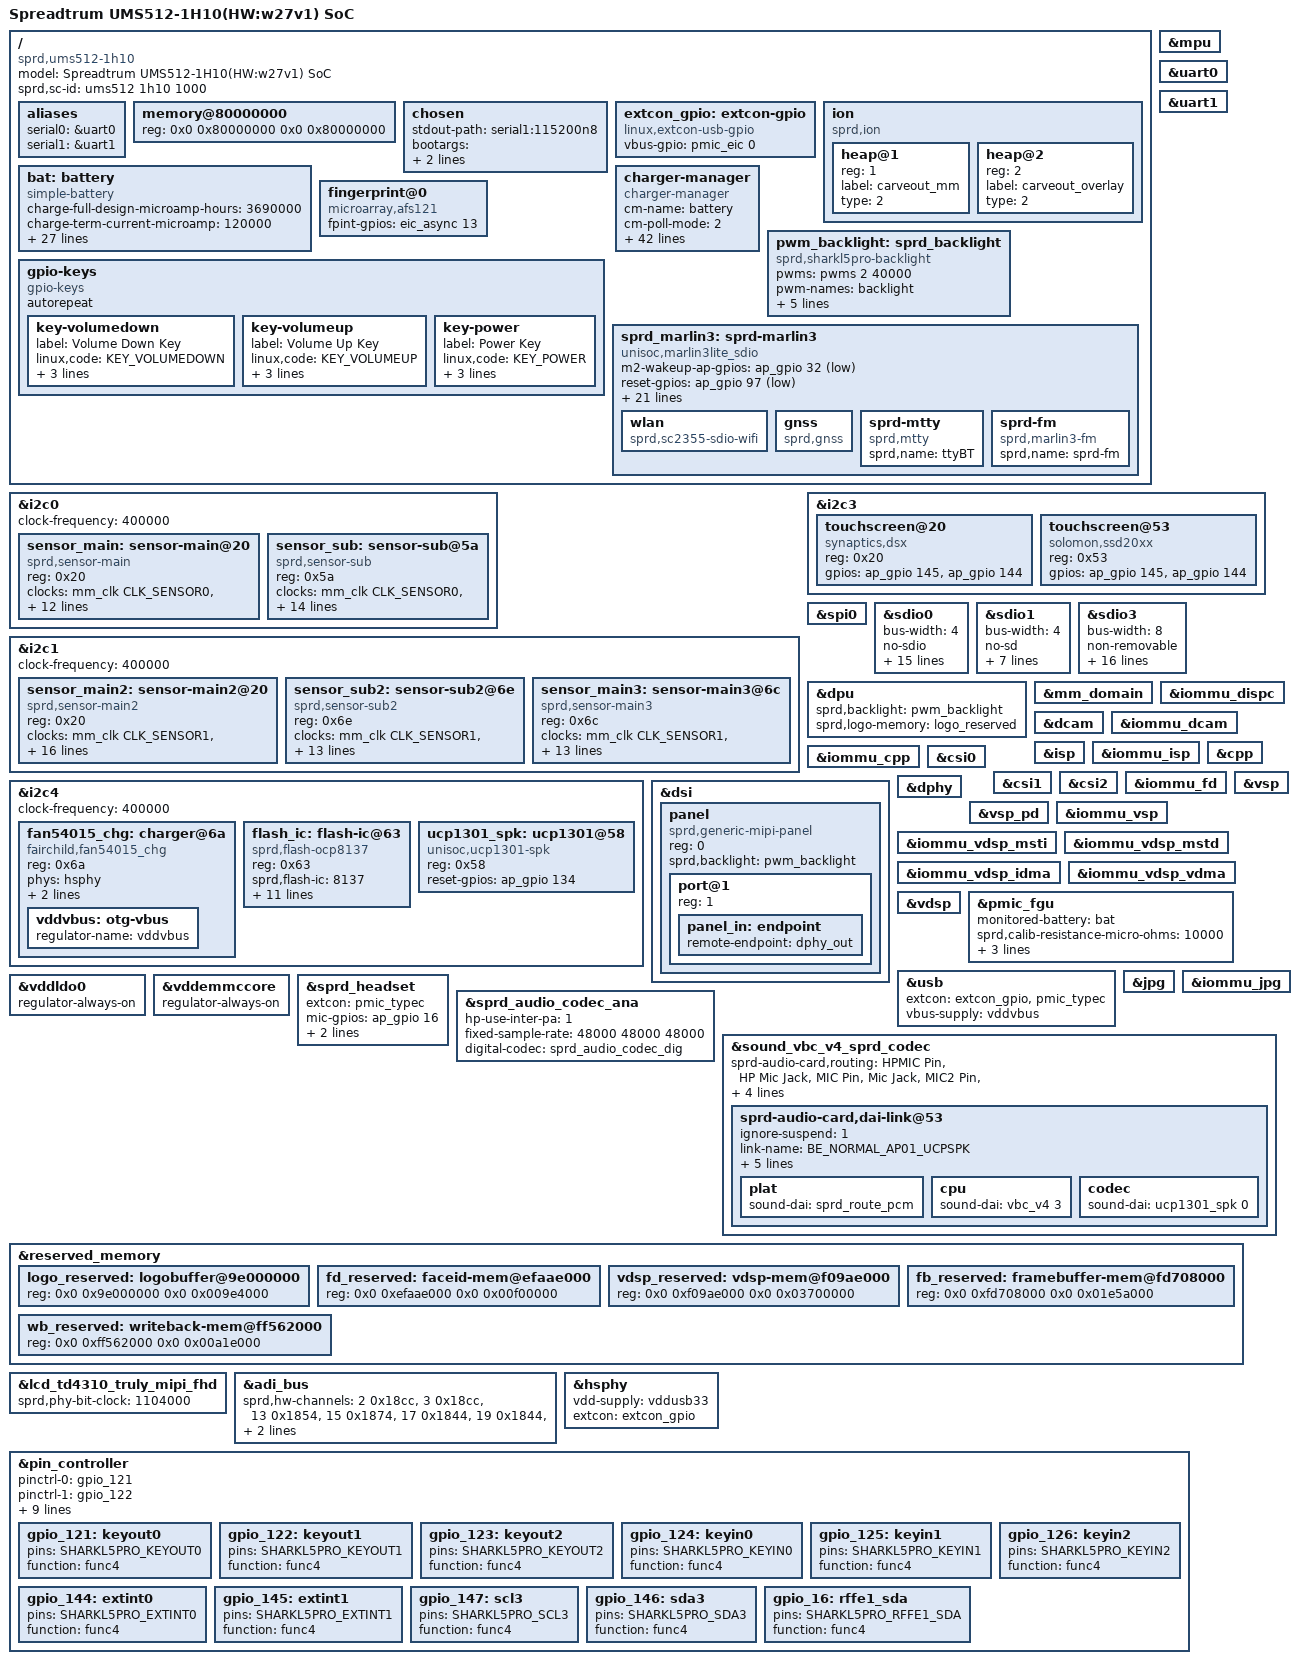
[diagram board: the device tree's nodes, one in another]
// SPDX-License-Identifier: GPL-2.0-only
/*
 * Unisoc UMS512-1h10 boards DTS file
 *
 * Copyright (C) 2020, Unisoc Inc.
 */

/dts-v1/;

#include <dt-bindings/clock/sprd,ums512-clk.h>
#include <dt-bindings/input/input.h>
#include <dt-bindings/gpio/gpio.h>
#include "ums512.dtsi"
#include "sc2730.dtsi"
#include "sprd-sound-fe-be.dtsi"
#include "ums512-mach.dtsi"
#include <dt-bindings/mfd/sprd,sc2730-regs.h>
#include <dt-bindings/mfd/sprd,sc2730-mask.h>

#include "lcd/lcd_td4310_truly_mipi_fhd.dtsi"
#include "lcd/lcd_ssd2092_truly_mipi_fhd.dtsi"

/ {
	model = "Spreadtrum UMS512-1H10(HW:w27v1) SoC";

	compatible = "sprd,ums512-1h10", "sprd,ums512";

	sprd,sc-id = "ums512 1h10 1000";

	aliases {
		serial0 = &uart0;
		serial1 = &uart1;
	};

	memory@80000000 {
		device_type = "memory";
		reg = <0x0 0x80000000 0x0 0x80000000>;
	};

	chosen: chosen {
		stdout-path = "serial1:115200n8";
		bootargs = "earlycon console=ttyS1,115200n8 loglevel=1 init=/init root=/dev/ram0 rw printk.devkmsg=on androidboot.boot_devices=soc/soc:ap-apb/71400000.sdio dummy_hcd.num=0";
	};

	extcon_gpio: extcon-gpio {
		compatible = "linux,extcon-usb-gpio";
		vbus-gpio = <&pmic_eic 0 GPIO_ACTIVE_HIGH>;
	};

	ion: ion {
		compatible = "sprd,ion";
		#address-cells = <1>;
		#size-cells = <0>;

		heap@1 {
			reg = <1>;
			label = "carveout_mm";
			type = <2>;
		};

		heap@2 {
			reg = <2>;
			label = "carveout_overlay";
			type = <2>;
		};
	};

	bat: battery {
		compatible = "simple-battery";
		charge-full-design-microamp-hours = <3690000>;
		charge-term-current-microamp = <120000>;
		constant-charge-voltage-max-microvolt = <4400000>;
		factory-internal-resistance-micro-ohms = <130000>;
		voltage-min-design-microvolt = <3450000>;
		ocv-capacity-celsius = <20>;
		ocv-capacity-table-0 = <4380000 100>, <4317000 95>, <4258000 90>,
					<4200000 85>, <4145000 80>, <4092000 75>,
					<4047000 70>, <3990000 65>, <3955000 60>,
					<3900000 55>, <3861000 50>, <3834000 45>,
					<3813000 40>, <3796000 35>, <3783000 30>,
					<3770000 25>, <3752000 20>, <3730000 15>,
					<3698000 10>, <3687000 5>, <3400000 0>;
		voltage-temp-table = <1095000 800>, <986000 850>, <878000 900>,
				      <775000 950>, <678000 1000>, <590000 1050>,
				      <510000 1100>, <440000 1150>, <378000 1200>,
				      <324000 1250>, <278000 1300>, <238000 1350>,
				      <204000 1400>, <175000 1450>, <150000 1500>,
				      <129000 1550>, <111000 1600>, <96000 1650>;
		capacity-temp-table = <45 100>, <25 100>, <10 98>, <0 93>, <(-10) 85>, <(-20) 64>;
		resistance-temp-table = <45 77>, <25 100>, <10 546>, <0 769>, <(-10) 892>, <(-20) 923>;
		charge-sdp-current-microamp = <500000 500000>;
		charge-dcp-current-microamp = <1150000 3000000>;
		charge-cdp-current-microamp = <1150000 1150000>;
		charge-unknown-current-microamp = <1050000 1050000>;
	};

	charger-manager {
		compatible = "charger-manager";
		cm-name = "battery";
		cm-poll-mode = <2>;
		cm-poll-interval = <15000>;
		cm-battery-stat = <2>;

		cm-fullbatt-vchkdrop-ms = <30000>;
		cm-fullbatt-vchkdrop-volt = <60000>;
		cm-fullbatt-voltage = <4350000>;
		cm-fullbatt-current = <120000>;
		cm-fullbatt-capacity = <100>;

		cm-num-chargers = <1>;
		cm-chargers = "fan54015_charger";
		cm-fuel-gauge = "sc27xx-fgu";

		/* in deci centigrade */
		cm-battery-cold = <200>;
		cm-battery-cold-in-minus;
		cm-battery-hot = <800>;
		cm-battery-temp-diff = <100>;

		/* Allow charging for 6hr */
		cm-charging-max = <21600000>;
		/* recovery charging after stop charging 45min */
		cm-discharging-max = <2700000>;

		/* the interval to feed charger watchdog */
		cm-wdt-interval = <60>;

		/* drop voltage in microVolts to allow shutdown */
		cm-shutdown-voltage = <3100000>;

		/* when 99% of the time is exceeded, it will be forced to 100% */
		cm-tickle-time-out = <1500>;

		/* how much time to allow capacity change */
		cm-one-cap-time = <30>;

		/* when the safe charging voltage is exceeded, stop charging */
		cm-charge-voltage-max = <6500000>;
		/* drop voltage in microVolts to restart charging */
		cm-charge-voltage-drop = <700000>;
		cm-dcp-jeita-temp-table = <1000 1030 0 4400000>, <1150 1180 700000 4400000>,
			<1450 1420 1150000 4400000>, <1600 1570 700000 4100000>;
		cm-sdp-jeita-temp-table = <1000 1030 0 4400000>, <1150 1180 500000 4400000>,
			<1450 1420 500000 4400000>, <1600 1570 500000 4100000>;
		cm-cdp-jeita-temp-table = <1000 1030 0 4400000>, <1150 1180 700000 4400000>,
			<1450 1420 1150000 4400000>, <1600 1570 700000 4100000>;
		cm-unknown-jeita-temp-table = <1000 1030 0 4400000>, <1150 1180 700000 4400000>,
			<1450 1420 1050000 4400000>, <1600 1570 700000 4100000>;

		monitored-battery = <&bat>;

		cm-cap-remap-table = <1 2 3>, <2 3 2>, <98 99 2>, <99 100 3>;

	};

	fingerprint@0 {
		compatible = "microarray,afs121";
		fpint-gpios = <&eic_async 13 0>;
	};

	pwm_backlight: sprd_backlight {
		compatible = "sprd,sharkl5pro-backlight";
		pwms = <&pwms 2 40000>;
		pwm-names = "backlight";
		sprd,max-brightness-level = <880>;
		default-brightness-level = <250>;
		sprd,brightness-scale = <1023>;
		brightness-levels = <
					  0   3   4   5   6   7
			  8   9  10  11  12  13  14  15  16  17
			 18  19  20  21  22  23  24  25  26  27
			 28  29  31  33  35  37  39  41  43  45
			 46  48  50  52  54  56  58  60  62  64
			 66  68  70  72  74  76  78  80  82  84
			 86  88  90  92  94  96  98 100 102 104
			106 108 110 112 114 116 118 120 122 124
			126 128 130 132 134 136 138 140 142 144
			146 148 150 152 154 156 158 160 162 164
			166 169 172 175 178 181 184 187 190 193
			196 199 202 205 208 211 214 217 220 223
			226 229 232 235 238 241 244 247 250 253
			256 259 262 265 268 271 274 277 280 283
			286 290 294 298 302 306 310 314 318 322
			326 330 334 338 342 346 350 354 358 362
			366 370 374 378 382 386 390 394 398 402
			406 410 414 418 422 426 430 434 438 442
			446 451 456 461 466 471 476 481 486 491
			496 501 506 511 516 521 526 531 536 541
			546 551 556 561 566 571 576 581 586 591
			596 601 606 611 616 621 626 631 636 641
			646 652 658 664 670 676 682 688 694 700
			706 712 718 724 730 736 742 748 754 760
			766 772 778 784 790 796 802 808 814 820
			826 832 838 844 850 856 862 868 874 880
			>;
	};

	gpio-keys {
		compatible = "gpio-keys";
		autorepeat;

		key-volumedown {
			label = "Volume Down Key";
			linux,code = <KEY_VOLUMEDOWN>;
			gpios = <&ap_gpio 124 GPIO_ACTIVE_LOW>;
			debounce-interval = <2>;
			wakeup-source;
		};

		key-volumeup {
			label = "Volume Up Key";
			linux,code = <KEY_VOLUMEUP>;
			gpios = <&pmic_eic 4 GPIO_ACTIVE_HIGH>;
			debounce-interval = <2>;
			wakeup-source;
		};

		key-power {
			label = "Power Key";
			linux,code = <KEY_POWER>;
			gpios = <&pmic_eic 1 GPIO_ACTIVE_LOW>;
			debounce-interval = <2>;
			wakeup-source;
		};
	};

	sprd_marlin3: sprd-marlin3 {
		compatible = "unisoc,marlin3lite_sdio";
		m2-wakeup-ap-gpios = <&ap_gpio 32 GPIO_ACTIVE_LOW>;
		reset-gpios = <&ap_gpio 97 GPIO_ACTIVE_LOW>;
		enable-gpios = <&ap_gpio 143 GPIO_ACTIVE_LOW>;
		m2-to-ap-irq-gpios = <&ap_gpio 96 GPIO_ACTIVE_LOW>;
		avdd12-supply = <&vddwcn>;
		avdd33-supply = <&vddwifipa>;
		dcxo18-supply = <&vddsim2>;

		clock-names = "clk_32k","source","enable";
		clocks = <&aon_clk CLK_AUX0>,
			 <&ext_32k>,
			 <&aonapb_gate CLK_AUX0_EB>;

		extcon = <&sdio1>;
		sdhci-name = <&sdio1>;

		sprd,btwf-file-name = "/dev/block/platform/soc/soc:ap-apb/71400000.sdio/by-name/wcnmodem";
		sprd,gnss-file-name = "/vendor/firmware/gnssmodem.bin";
		adma-tx;
		adma-rx;
		/*
		 * bound parameter:
		 * [0]:addr offset, [1]:mask, [2]:unboundval, [3]:boundval
		 */
		avdd12-parent-bound-chip = <REG_ANA_SLP_DCDC_PD_CTRL MASK_ANA_SLP_DCDCGEN1_PD_EN 0x0 MASK_ANA_SLP_DCDCGEN1_PD_EN>;
		avdd12-bound-wbreq = <REG_ANA_LDO_XTL_EN10 MASK_ANA_LDO_VDDWCN_EXT_XTL3_EN 0x0 MASK_ANA_LDO_VDDWCN_EXT_XTL3_EN>;
		avdd33-bound-wbreq = <REG_ANA_LDO_XTL_EN11 MASK_ANA_LDO_VDDWIFIPA_EXT_XTL3_EN 0x0 MASK_ANA_LDO_VDDWIFIPA_EXT_XTL3_EN>;

		wlan {
			compatible = "sprd,sc2355-sdio-wifi";
		};

		gnss {
			compatible = "sprd,gnss";
		};

		sprd-mtty {
			compatible = "sprd,mtty";
			sprd,name = "ttyBT";
		};

		sprd-fm {
			compatible = "sprd,marlin3-fm";
			sprd,name = "sprd-fm";
		};
	};
};

&mpu {
	status = "okay";
};

&uart0 {
	status = "okay";
};

&uart1 {
	status = "okay";
};

&i2c0 {
	status = "okay";
	clock-frequency = <400000>;

	sensor_main: sensor-main@20 {
		compatible = "sprd,sensor-main";
		reg = <0x20>;
		clock-names = "clk_src","sensor_eb",
			"clk_96m","clk_76m8",
			"clk_48m","clk_26m";
		clocks = <&mm_clk CLK_SENSOR0>,<&mm_gate CLK_MM_SENSOR0_EB>,
				<&pll2 CLK_TWPLL_96M>,<&pll2 CLK_TWPLL_76M8>,
				<&pll2 CLK_TWPLL_48M>,<&ext_26m>;
		vddio-supply = <&vddcamio>;
		vddcama-supply = <&vddcama0>;
		vddcamd-supply = <&vddcamd0>;
		vddcammot-supply = <&vddcammot>;
		reset-gpios = <&ap_gpio 44 0>;
		power-down-gpios = <&ap_gpio 46 0>;
		sprd,phyid = <0>;
		csi = <&csi0>;
		power-domains = <&mm_domain>;
	};

	sensor_sub: sensor-sub@5a {
		compatible = "sprd,sensor-sub";
		reg = <0x5a>;
		clock-names = "clk_src","sensor_eb",
			"clk_96m","clk_76m8",
			"clk_48m","clk_26m";
		clocks = <&mm_clk CLK_SENSOR0>,<&mm_gate CLK_MM_SENSOR0_EB>,
				<&pll2 CLK_TWPLL_96M>,<&pll2 CLK_TWPLL_76M8>,
				<&pll2 CLK_TWPLL_48M>,<&ext_26m>;
		vddio-supply = <&vddcamio>;
		vddcama-supply = <&vddcama0>;
		vddcamd-supply = <&vddcamd0>;
		vddcammot-supply = <&vddcammot>;
		reset-gpios = <&ap_gpio 41 0>;
		power-down-gpios = <&ap_gpio 40 0>;
		mipi-switch-en-gpios = <&ap_gpio 55 0>;
		mipi-switch-mode-gpios = <&ap_gpio 8 0>;
		sprd,phyid = <1>;
		csi = <&csi1>;
		power-domains = <&mm_domain>;
	};
};

&i2c1 {
	status = "okay";
	clock-frequency = <400000>;

	sensor_main2: sensor-main2@20 {
		compatible = "sprd,sensor-main2";
		reg = <0x20>;
		clock-names = "clk_src","sensor_eb",
			"clk_96m","clk_76m8",
			"clk_48m","clk_26m";
		clocks = <&mm_clk CLK_SENSOR1>,<&mm_gate CLK_MM_SENSOR1_EB>,
				<&pll2 CLK_TWPLL_96M>,<&pll2 CLK_TWPLL_76M8>,
				<&pll2 CLK_TWPLL_48M>,<&ext_26m>;
		vddio-supply = <&vddcamio>;
		vddcama-supply = <&vddcama1>;
		vddcamd-supply = <&vddcamd1>;
		vddcammot-supply = <&vddcammot>;
		avdd-gpios = <&ap_gpio 33 0>;
		mot-gpios = <&ap_gpio 88 0>;
		reset-gpios = <&ap_gpio 45 0>;
		power-down-gpios = <&ap_gpio 47 0>;
		mipi-switch-en-gpios = <&ap_gpio 55 0>;
		mipi-switch-mode-gpios = <&ap_gpio 8 0>;
		sprd,phyid = <1>;
		csi = <&csi1>;
		power-domains = <&mm_domain>;
	};

	sensor_sub2: sensor-sub2@6e {
		compatible = "sprd,sensor-sub2";
		reg = <0x6e>;
		clock-names = "clk_src","sensor_eb",
			"clk_96m","clk_76m8",
			"clk_48m","clk_26m";
		clocks = <&mm_clk CLK_SENSOR1>,<&mm_gate CLK_MM_SENSOR1_EB>,
			<&pll2 CLK_TWPLL_96M>,<&pll2 CLK_TWPLL_76M8>,
			<&pll2 CLK_TWPLL_48M>,<&ext_26m>;
		vddio-supply = <&vddcamio>;
		vddcama-supply = <&vddcama1>;
		vddcamd-supply = <&vddcamd1>;
		vddcammot-supply = <&vddcammot>;
		mot-gpios = <&ap_gpio 88 0>;
		reset-gpios = <&ap_gpio 41 0>;
		power-down-gpios = <&ap_gpio 40 0>;
		sprd,phyid = <2>;
		csi = <&csi2>;
		power-domains = <&mm_domain>;
	};

	sensor_main3: sensor-main3@6c {
		compatible = "sprd,sensor-main3";
		reg = <0x6c>;
		clock-names = "clk_src","sensor_eb",
			"clk_96m","clk_76m8",
			"clk_48m","clk_26m";
		clocks = <&mm_clk CLK_SENSOR1>,<&mm_gate CLK_MM_SENSOR1_EB>,
				<&pll2 CLK_TWPLL_96M>,<&pll2 CLK_TWPLL_76M8>,
				<&pll2 CLK_TWPLL_48M>,<&ext_26m>;
		vddio-supply = <&vddcamio>;
		vddcama-supply = <&vddcama1>;
		vddcamd-supply = <&vddcamd1>;
		vddcammot-supply = <&vddcammot>;
		mot-gpios = <&ap_gpio 88 0>;
		reset-gpios = <&ap_gpio 41 0>;
		power-down-gpios = <&ap_gpio 40 0>;
		sprd,phyid = <2>;
		csi = <&csi2>;
		power-domains = <&mm_domain>;
	};
};

&i2c3 {
	#address-cells = <1>;
	#size-cells = <0>;

	status = "okay";

	touchscreen@20 {
		compatible = "synaptics,dsx";
		reg = <0x20>;
		gpios = <&ap_gpio 145 GPIO_ACTIVE_HIGH>,
			<&ap_gpio 144 GPIO_ACTIVE_HIGH>;
	};

	touchscreen@53 {
		compatible = "solomon,ssd20xx";
		reg = <0x53>;
		gpios = <&ap_gpio 145 GPIO_ACTIVE_HIGH>,
			<&ap_gpio 144 GPIO_ACTIVE_HIGH>;
	};

};

&i2c4 {
	status = "okay";
	clock-frequency = <400000>;

	fan54015_chg: charger@6a {
		compatible = "fairchild,fan54015_chg";
		reg = <0x6a>;
		phys = <&hsphy>;
		monitored-battery = <&bat>;
		extcon = <&extcon_gpio>;
		vddvbus:otg-vbus {
			regulator-name = "vddvbus";
		};
	};

	flash_ic: flash-ic@63 {
		compatible = "sprd,flash-ocp8137";
		reg = <0x63>;
		sprd,flash-ic = <8137>;
		sprd,torch = <1>;
		sprd,preflash = <1>;
		sprd,highlight = <1>;
		sprd,torch-level = <128>;
		sprd,preflash-level = <128>;
		sprd,highlight-level = <128>;
		sprd,lvfm-enable = <1>;
		flash-chip-en-gpios = <&ap_gpio 136 0>;
		flash-torch-en-gpios = <&ap_gpio 139 0>;
		flash-en-gpios = <&ap_gpio 137 0>;
		flash-sync-gpios = <&ap_gpio 138 0>;
	};

	ucp1301_spk: ucp1301@58 {
		compatible = "unisoc,ucp1301-spk";
		reg = <0x58>;
		reset-gpios = <&ap_gpio 134 GPIO_ACTIVE_HIGH>;
		#sound-dai-cells = <1>;
	};
};

&spi0 {
	/*used for fingerprint sensor*/
	status = "okay";
};

&sdio0 {
	bus-width = <4>;
	no-sdio;
	no-mmc;
	status = "okay";
};

&sdio1 {
	bus-width = <4>;
	no-sd;
	no-mmc;
	status = "okay";
};

&sdio3 {
	bus-width = <8>;
	non-removable;
	no-sdio;
	no-sd;
	cap-mmc-hw-reset;
	status = "okay";
};

&dpu {
	status = "okay";
};

&mm_domain {
	status = "okay";
};

&iommu_dispc {
	status = "okay";
};

&dcam {
	status = "okay";
};

&iommu_dcam {
	status = "okay";
};

&isp {
	status = "okay";
};

&iommu_isp {
	status = "okay";
};

&cpp {
	status = "okay";
};

&iommu_cpp {
	status = "okay";
};

&csi0 {
	status = "okay";
};

&csi1 {
	status = "okay";
};

&csi2 {
	status = "okay";
};

&iommu_fd {
	status = "okay";
};

&dsi {
	status = "okay";
	#address-cells = <1>;
	#size-cells = <0>;

	panel: panel {
		compatible = "sprd,generic-mipi-panel";
		#address-cells = <1>;
		#size-cells = <0>;
		reg = <0>;

		port@1 {
			reg = <1>;
			panel_in: endpoint {
				remote-endpoint = <&dphy_out>;
			};
		};
	};
};

&dphy {
	status = "okay";
};

&vsp {
	status = "okay";
};

&vsp_pd {
	status = "okay";
};

&iommu_vsp {
	status = "okay";
};

&iommu_vdsp_msti {
	status = "okay";
};

&iommu_vdsp_mstd {
	status = "okay";
};

&iommu_vdsp_idma {
	status = "okay";
};

&iommu_vdsp_vdma {
	status = "okay";
};

&vdsp {
	status = "okay";
};

&pmic_fgu {
	monitored-battery = <&bat>;
	sprd,calib-resistance-micro-ohms = <10000>;
	sprd,comp-resistance-mohm = <20>;
	first-calib-voltage = <3630000>;
	first-calib-capacity = <40>;
};

&usb {
	extcon = <&extcon_gpio>, <&pmic_typec>;
	vbus-supply = <&vddvbus>;
};

&jpg {
	status = "okay";
};

&iommu_jpg {
	status = "okay";
};

&vddldo0 {
	regulator-always-on;
};

&vddemmccore {
	regulator-always-on;
};

&sprd_headset {
	status = "okay";
	extcon = <&pmic_typec>;
	mic-gpios = <&ap_gpio 16 GPIO_ACTIVE_HIGH>;
	lr-gpios = <&ap_gpio 15 GPIO_ACTIVE_HIGH>;
	sprd,3pole-adc-threshold = <112>;
};

&sprd_audio_codec_ana {
	status = "okay";
	hp-use-inter-pa = <1>;
	fixed-sample-rate = <48000 48000 48000>;
	digital-codec = <&sprd_audio_codec_dig>;
};

&sound_vbc_v4_sprd_codec {
	status = "okay";
	sprd-audio-card,routing =
		"HPMIC Pin", "HP Mic Jack",
		"MIC Pin", "Mic Jack",
		"MIC2 Pin", "Aux Mic Jack",
		"HeadPhone Jack", "HP Pin",
		"Ext Spk", "SPK Pin",
		"UCP1301 SPK ON", "SPK Pin",
		"Ext Spk", "UCP1301 SPK",
		"DMIC Pin", "DMic Jack",
		"DMIC1 Pin", "DMic1 Jack",
		"Ext Ear", "EAR Pin";

	/* 35: ucp1301 normal ap01 */
	sprd-audio-card,dai-link@53 {
		ignore-suspend = <1>;
		link-name = "BE_NORMAL_AP01_UCPSPK";
		stream-name = "BE_ST_NORMAL_AP01_UCPSPK";
		no-pcm = <1>;
		dpcm-playback = <1>;
		be-id = <0>;
		dai-format = "i2s";
		plat {
			sound-dai = <&sprd_route_pcm>;
		};
		cpu {
			sound-dai = <&vbc_v4 3>;
		};
		codec {
			sound-dai = <&ucp1301_spk 0>;
		};
	};

	/*
	 * node 54 and node 55 (index 36 and 37) are reserved for
	 * "ucp1301-spk2" and "ucp1301-rcv"
	 * nodes from 56 to 67 (index from 38 to 49) are used by HIFI
	 */
};

&panel {
	sprd,backlight = <&pwm_backlight>;
};

&dpu {
	sprd,backlight = <&pwm_backlight>;
	sprd,logo-memory = <&logo_reserved>;
};

&chosen {
	bootargs_ext = "androidboot.hardware=ums512_1h10";
};

&reserved_memory {
	#address-cells = <2>;
	#size-cells = <2>;

	logo_reserved: logobuffer@9e000000{
		reg = <0x0 0x9e000000 0x0 0x009e4000>;
	};

	fd_reserved: faceid-mem@efaae000 {
		reg = <0x0 0xefaae000 0x0 0x00f00000>;
	};

	vdsp_reserved: vdsp-mem@f09ae000 {
		reg = <0x0 0xf09ae000 0x0 0x03700000>;
	};

	fb_reserved: framebuffer-mem@fd708000 {
		reg = <0x0 0xfd708000 0x0 0x01e5a000>;
	};

	wb_reserved: writeback-mem@ff562000 {
		reg = <0x0 0xff562000 0x0 0x00a1e000>;
	};

};

&lcd_td4310_truly_mipi_fhd {
	sprd,phy-bit-clock = <1104000>;  /* kbps */
};

&adi_bus {
	sprd,hw-channels = <2 0x18cc>, <3 0x18cc>, <13 0x1854>, <15 0x1874>,
			   <17 0x1844>, <19 0x1844>, <21 0x1864>, <30 0x1820>,
			   <32 0x197c>, <33 0x1988>, <35 0x19b8>, <39 0x19ac>;
};

&vddldo0 {
	regulator-always-on;
};

&hsphy {
	vdd-supply = <&vddusb33>;
	extcon = <&extcon_gpio>;
	status = "okay";
};

&usb {
	extcon = <&extcon_gpio>, <&pmic_typec>;
	status = "okay";
	vbus-supply = <&vddvbus>;
};

&sdio0 {
	cd-gpios = <&eic_sync 19 GPIO_ACTIVE_HIGH>;
	sprd,phy-delay-sd-uhs-sdr104 = <0x7f 0x73 0x72 0x72>;
	sprd,phy-delay-sd-uhs-sdr50 = <0x6e 0x7f 0x01 0x01>;
	sprd,phy-delay-sd-highspeed = <0x7f 0x1a 0x9a 0x9a>;
	sprd,phy-delay-legacy = <0x7f 0x1a 0x9a 0x9a>;
	vmmc-supply = <&vddsdcore>;
	vqmmc-supply = <&vddsdio>;
	sd-uhs-sdr104;
	sd-uhs-sdr50;
	cap-mmc-hw-reset;
	sprd,name = "sdio_sd";
	status = "okay";
};

&sdio1 {
	sprd,phy-delay-sd-uhs-sdr104 = <0x7f 0x76 0x69 0x69>;
	sprd,phy-delay-sd-uhs-sdr50 = <0x7f 0xf7 0xf5 0xf5>;
	sd-uhs-sdr104;
	sd-uhs-sdr50;
};

&sdio3 {
	sprd,phy-delay-mmc-hs400es = <0x40 0x7f 0x2d 0x2d>;
	sprd,phy-delay-mmc-hs400 = <0x3f 0xdf 0x2f 0x2f>;
	sprd,phy-delay-mmc-hs200 = <0x7f 0xde 0xd4 0xd4>;
	sprd,phy-delay-mmc-ddr52 = <0x3e 0x37 0x24 0x24>;
	sprd,phy-delay-mmc-highspeed = <0x60 0xb7 0x34 0x34>;
	vmmc-supply = <&vddemmccore>;
	voltage-ranges = <3000 3000>;
	bus-width = <8>;
	non-removable;
	cap-mmc-hw-reset;
	mmc-hs400-enhanced-strobe;
	mmc-hs400-1_8v;
	mmc-hs200-1_8v;
	mmc-ddr-1_8v;
	no-sdio;
	no-sd;
	status = "okay";
};

&pin_controller {
	pinctrl-names =
	/* keyout0 ~ keyout2 */
	"gpio_121", "gpio_122", "gpio_123",
	/* keyin0 ~ keyin2 */
	"gpio_124", "gpio_125", "gpio_126",
	/* extint0, extint1, scl3, sda3, sda */
	"gpio_144", "gpio_145", "gpio_146", "gpio_147", "gpio_16";

	pinctrl-0 = <&gpio_121>;
	pinctrl-1 = <&gpio_122>;
	pinctrl-2 = <&gpio_123>;
	pinctrl-3 = <&gpio_124>;
	pinctrl-4 = <&gpio_125>;
	pinctrl-5 = <&gpio_126>;
	pinctrl-6 = <&gpio_144>;
	pinctrl-7 = <&gpio_145>;
	pinctrl-8 = <&gpio_146>;
	pinctrl-9 = <&gpio_147>;
	pinctrl-10 = <&gpio_16>;

	gpio_121: keyout0 {
		pins = "SHARKL5PRO_KEYOUT0";
		function = "func4";
	};

	gpio_122: keyout1 {
		pins = "SHARKL5PRO_KEYOUT1";
		function = "func4";
	};

	gpio_123: keyout2 {
		pins = "SHARKL5PRO_KEYOUT2";
		function = "func4";
	};

	gpio_124: keyin0 {
		pins = "SHARKL5PRO_KEYIN0";
		function = "func4";
	};

	gpio_125: keyin1 {
		pins = "SHARKL5PRO_KEYIN1";
		function = "func4";
	};

	gpio_126: keyin2 {
		pins = "SHARKL5PRO_KEYIN2";
		function = "func4";
	};

	gpio_144: extint0 {
		pins = "SHARKL5PRO_EXTINT0";
		function = "func4";
	};

	gpio_145: extint1 {
		pins = "SHARKL5PRO_EXTINT1";
		function = "func4";
	};

	gpio_147: scl3 {
		pins = "SHARKL5PRO_SCL3";
		function = "func4";
	};

	gpio_146: sda3 {
		pins = "SHARKL5PRO_SDA3";
		function = "func4";
	};

	gpio_16: rffe1_sda {
		pins = "SHARKL5PRO_RFFE1_SDA";
		function = "func4";
	};
};
